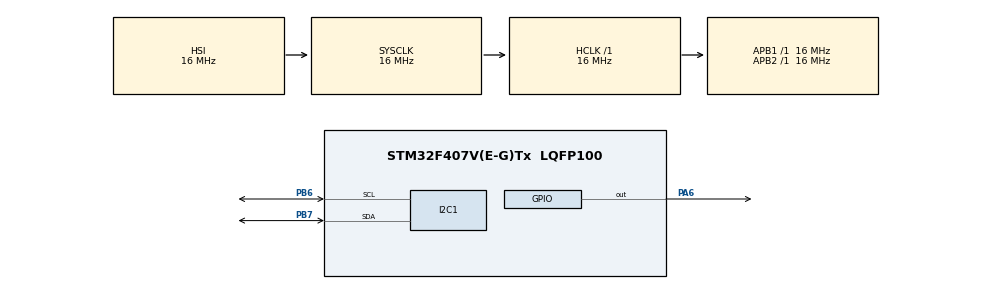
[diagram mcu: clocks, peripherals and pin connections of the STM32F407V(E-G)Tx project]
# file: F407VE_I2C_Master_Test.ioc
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I2C1.I2C_Mode=I2C_Standard
I2C1.OwnAddress=8
Mcu.Family=STM32F4
Mcu.Name=STM32F407V(E-G)Tx
Mcu.Package=LQFP100
NVIC.PriorityGroup=NVIC_PRIORITYGROUP_4
PA13.Mode=Trace_Asynchronous_SW
PA13.Signal=SYS_JTMS-SWDIO
PA14.Mode=Trace_Asynchronous_SW
PA14.Signal=SYS_JTCK-SWCLK
PA6.Signal=GPIO_Output
PB3.Mode=Trace_Asynchronous_SW
PB3.Signal=SYS_JTDO-SWO
PB6.Mode=I2C
PB6.Signal=I2C1_SCL
PB7.Mode=I2C
PB7.Signal=I2C1_SDA
PH0-OSC_IN.Mode=HSE-External-Oscillator
PH0-OSC_IN.Signal=RCC_OSC_IN
PH1-OSC_OUT.Mode=HSE-External-Oscillator
PH1-OSC_OUT.Signal=RCC_OSC_OUT
ProjectManager.HeapSize=0x200
ProjectManager.StackSize=0x400
ProjectManager.TargetToolchain=STM32CubeIDE
RCC.AHBFreq_Value=16000000
RCC.APB1Freq_Value=16000000
RCC.APB2Freq_Value=16000000
RCC.CortexFreq_Value=16000000
RCC.HSE_VALUE=25000000
RCC.HSI_VALUE=16000000
RCC.LSE_VALUE=32768
RCC.SYSCLKFreq_VALUE=16000000
RCC.VCOOutputFreq_Value=192000000
board=custom

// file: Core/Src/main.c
/* USER CODE BEGIN Header */
/**
  ******************************************************************************
  * @file           : main.c
  * @brief          : Main program body
  ******************************************************************************
  * @attention
  *
  * <h2><center>&copy; Copyright (c) 2020 STMicroelectronics.
  * All rights reserved.</center></h2>
  *
  * This software component is licensed by ST under BSD 3-Clause license,
  * the "License"; You may not use this file except in compliance with the
  * License. You may obtain a copy of the License at:
  *                        opensource.org/licenses/BSD-3-Clause
  *
  ******************************************************************************
  */
/* USER CODE END Header */

#include "main.h"

/* USER CODE BEGIN Includes */
#include <stdio.h>
/* USER CODE END Includes */

I2C_HandleTypeDef hi2c1;

void SystemClock_Config(void);
static void MX_GPIO_Init(void);
static void MX_I2C1_Init(void);

int main(void)
{

  /* MCU Configuration--------------------------------------------------------*/

  /* Reset of all peripherals, Initializes the Flash interface and the Systick. */
  HAL_Init();

  /* Configure the system clock */
  SystemClock_Config();

  /* Initialize all configured peripherals */
  MX_GPIO_Init();
  MX_I2C1_Init();

  /* Infinite loop */
  /* USER CODE BEGIN WHILE */
  while (1)
  {
	  // Send data to I2C slave with address 8 (8<<1)
	  HAL_I2C_Master_Transmit(&hi2c1, 8<<1, "9876543\r\n", 9, 1000);

	  HAL_Delay(1000);

	  // Retrieve data to I2C slave with address 8 (8<<1)
	  uint8_t rev[9];
	  HAL_I2C_Master_Receive(&hi2c1, 8<<1, rev, sizeof(rev), 1000);
	  rev[sizeof(rev)] = 0;
	  printf("%s\r\n", rev);

	  HAL_Delay(1000);

	  HAL_GPIO_TogglePin(GPIOA, GPIO_PIN_6);

    /* USER CODE END WHILE */

  }
}

void SystemClock_Config(void)
{
  RCC_OscInitTypeDef RCC_OscInitStruct = {0};
  RCC_ClkInitTypeDef RCC_ClkInitStruct = {0};

  /** Configure the main internal regulator output voltage
  */
  __HAL_RCC_PWR_CLK_ENABLE();
  __HAL_PWR_VOLTAGESCALING_CONFIG(PWR_REGULATOR_VOLTAGE_SCALE1);
  /** Initializes the CPU, AHB and APB busses clocks
  */
  RCC_OscInitStruct.OscillatorType = RCC_OSCILLATORTYPE_HSI;
  RCC_OscInitStruct.HSIState = RCC_HSI_ON;
  RCC_OscInitStruct.HSICalibrationValue = RCC_HSICALIBRATION_DEFAULT;
  RCC_OscInitStruct.PLL.PLLState = RCC_PLL_NONE;
  if (HAL_RCC_OscConfig(&RCC_OscInitStruct) != HAL_OK)
  {
    Error_Handler();
  }
  /** Initializes the CPU, AHB and APB busses clocks
  */
  RCC_ClkInitStruct.ClockType = RCC_CLOCKTYPE_HCLK|RCC_CLOCKTYPE_SYSCLK
                              |RCC_CLOCKTYPE_PCLK1|RCC_CLOCKTYPE_PCLK2;
  RCC_ClkInitStruct.SYSCLKSource = RCC_SYSCLKSOURCE_HSI;
  RCC_ClkInitStruct.AHBCLKDivider = RCC_SYSCLK_DIV1;
  RCC_ClkInitStruct.APB1CLKDivider = RCC_HCLK_DIV1;
  RCC_ClkInitStruct.APB2CLKDivider = RCC_HCLK_DIV1;

  if (HAL_RCC_ClockConfig(&RCC_ClkInitStruct, FLASH_LATENCY_0) != HAL_OK)
  {
    Error_Handler();
  }
}

static void MX_I2C1_Init(void)
{

  hi2c1.Instance = I2C1;
  hi2c1.Init.ClockSpeed = 100000;
  hi2c1.Init.DutyCycle = I2C_DUTYCYCLE_2;
  hi2c1.Init.OwnAddress1 = 16;
  hi2c1.Init.AddressingMode = I2C_ADDRESSINGMODE_7BIT;
  hi2c1.Init.DualAddressMode = I2C_DUALADDRESS_DISABLE;
  hi2c1.Init.OwnAddress2 = 0;
  hi2c1.Init.GeneralCallMode = I2C_GENERALCALL_DISABLE;
  hi2c1.Init.NoStretchMode = I2C_NOSTRETCH_DISABLE;
  if (HAL_I2C_Init(&hi2c1) != HAL_OK)
  {
    Error_Handler();
  }

}

static void MX_GPIO_Init(void)
{
  GPIO_InitTypeDef GPIO_InitStruct = {0};

  /* GPIO Ports Clock Enable */
  __HAL_RCC_GPIOH_CLK_ENABLE();
  __HAL_RCC_GPIOA_CLK_ENABLE();
  __HAL_RCC_GPIOB_CLK_ENABLE();

  /*Configure GPIO pin Output Level */
  HAL_GPIO_WritePin(GPIOA, GPIO_PIN_6, GPIO_PIN_RESET);

  /*Configure GPIO pin : PA6 */
  GPIO_InitStruct.Pin = GPIO_PIN_6;
  GPIO_InitStruct.Mode = GPIO_MODE_OUTPUT_PP;
  GPIO_InitStruct.Pull = GPIO_NOPULL;
  GPIO_InitStruct.Speed = GPIO_SPEED_FREQ_LOW;
  HAL_GPIO_Init(GPIOA, &GPIO_InitStruct);

}

/* USER CODE BEGIN 4 */
int _write(int file, char *ptr, int len)
{
  /* Implement your write code here, this is used by puts and printf for example */
  int i=0;
  for(i=0 ; i<len ; i++)
    ITM_SendChar((*ptr++));
  return len;
}
/* USER CODE END 4 */

void Error_Handler(void)
{
}

/************************ (C) COPYRIGHT STMicroelectronics *****END OF FILE****/
